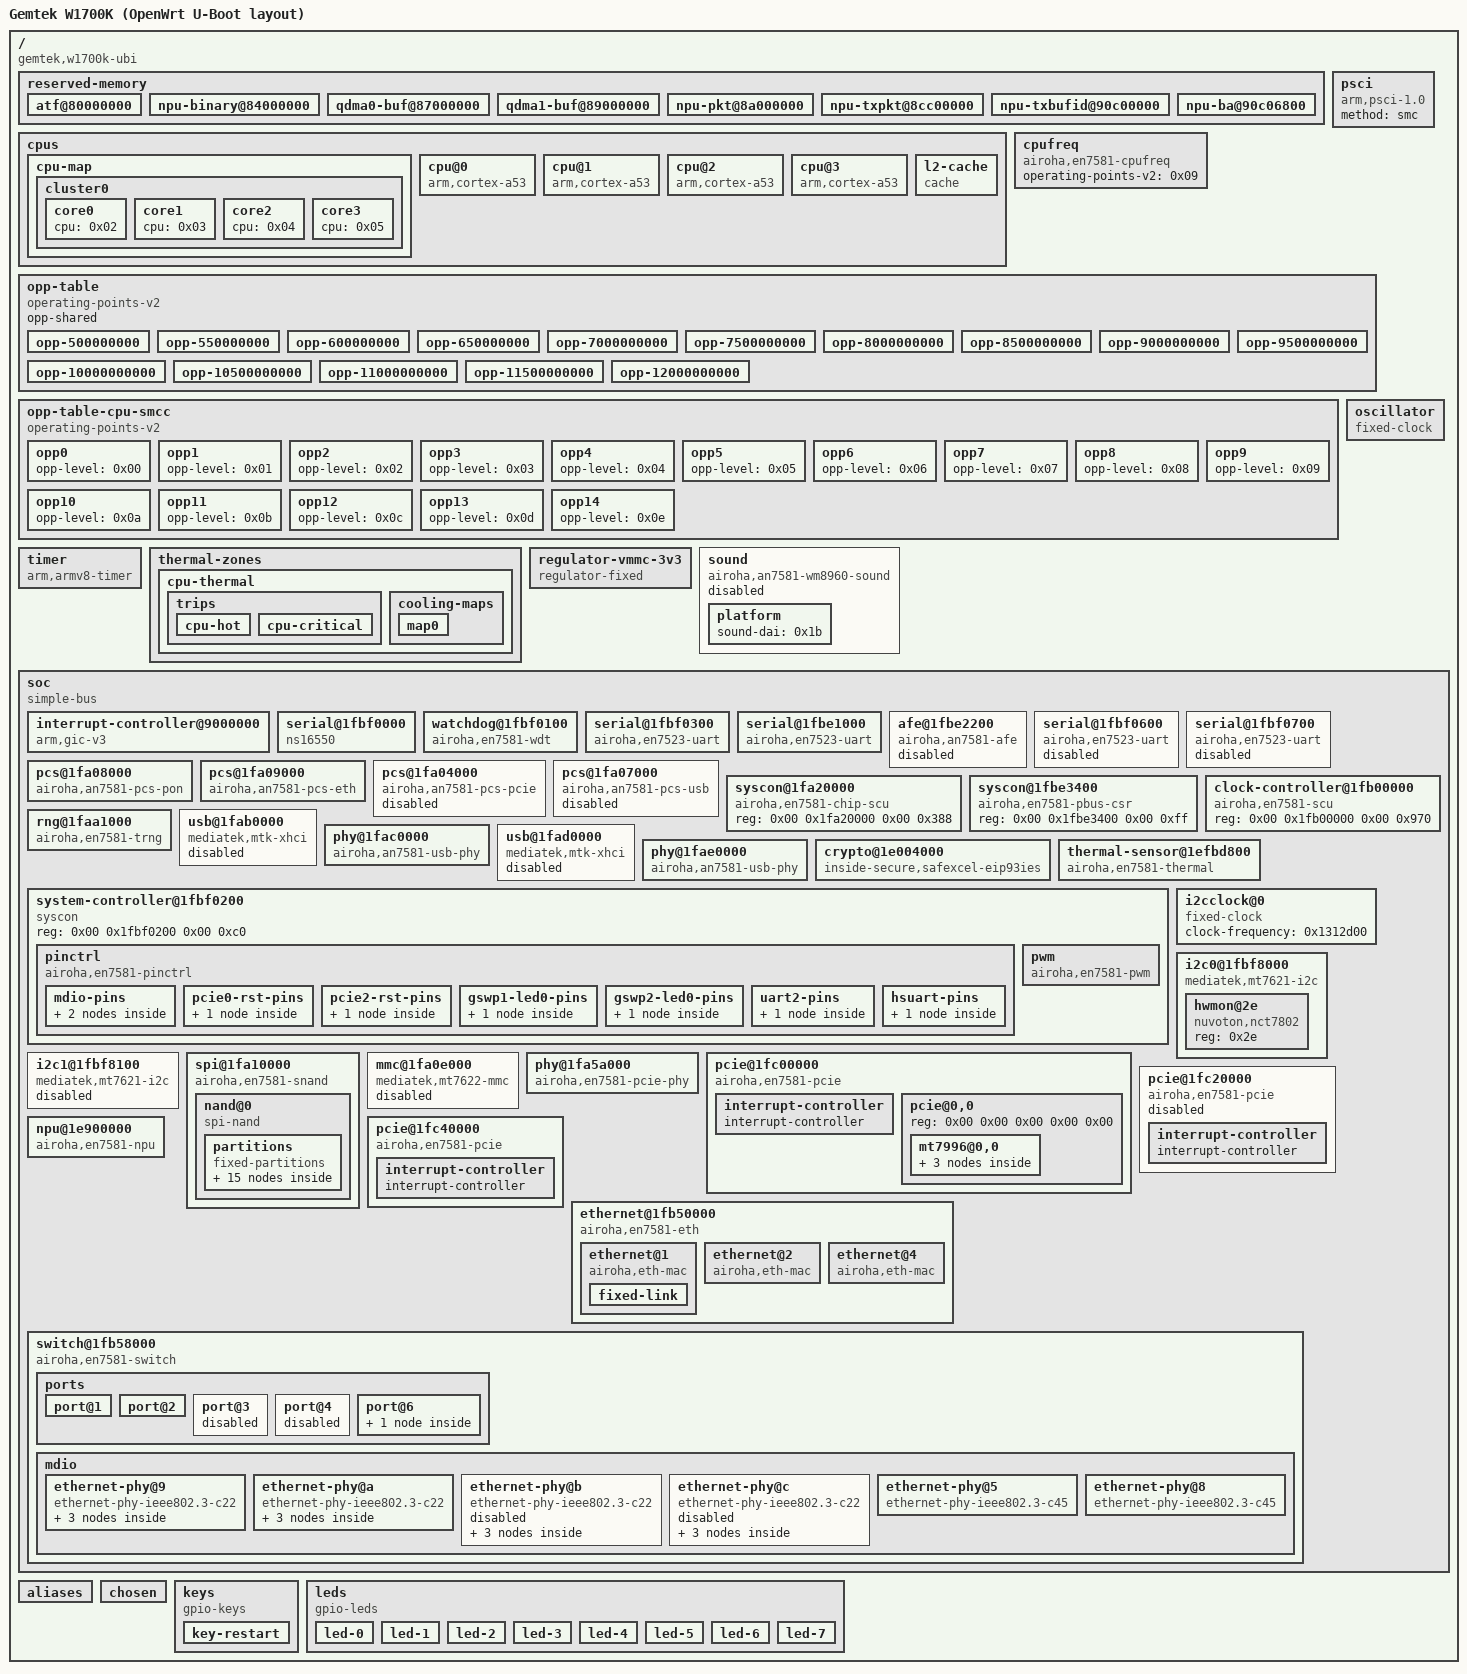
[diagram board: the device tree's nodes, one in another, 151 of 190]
/dts-v1/;

/ {
	interrupt-parent = <0x01>;
	#address-cells = <0x02>;
	#size-cells = <0x02>;
	model = "Gemtek W1700K (OpenWrt U-Boot layout)";
	compatible = "gemtek,w1700k-ubi", "airoha,an7581", "airoha,en7581";

	reserved-memory {
		#address-cells = <0x02>;
		#size-cells = <0x02>;
		ranges;

		atf@80000000 {
			no-map;
			reg = <0x00 0x80000000 0x00 0x200000>;
		};

		npu-binary@84000000 {
			no-map;
			reg = <0x00 0x84000000 0x00 0xa00000>;
			phandle = <0x31>;
		};

		qdma0-buf@87000000 {
			no-map;
			reg = <0x00 0x87000000 0x00 0x2000000>;
			phandle = <0x36>;
		};

		qdma1-buf@89000000 {
			no-map;
			reg = <0x00 0x89000000 0x00 0x1000000>;
			phandle = <0x37>;
		};

		npu-pkt@8a000000 {
			no-map;
			reg = <0x00 0x8a000000 0x00 0x2c00000>;
			phandle = <0x32>;
		};

		npu-txpkt@8cc00000 {
			no-map;
			reg = <0x00 0x8cc00000 0x00 0x4000000>;
			phandle = <0x33>;
		};

		npu-txbufid@90c00000 {
			no-map;
			reg = <0x00 0x90c00000 0x00 0x6800>;
			phandle = <0x34>;
		};

		npu-ba@90c06800 {
			no-map;
			reg = <0x00 0x90c06800 0x00 0x200000>;
			phandle = <0x35>;
		};
	};

	psci {
		compatible = "arm,psci-1.0";
		method = "smc";
	};

	cpus {
		#address-cells = <0x01>;
		#size-cells = <0x00>;

		cpu-map {

			cluster0 {

				core0 {
					cpu = <0x02>;
				};

				core1 {
					cpu = <0x03>;
				};

				core2 {
					cpu = <0x04>;
				};

				core3 {
					cpu = <0x05>;
				};
			};
		};

		cpu@0 {
			device_type = "cpu";
			compatible = "arm,cortex-a53";
			reg = <0x00>;
			operating-points-v2 = <0x06>;
			enable-method = "psci";
			clocks = <0x07>;
			clock-names = "cpu";
			power-domains = <0x07>;
			power-domain-names = "perf";
			next-level-cache = <0x08>;
			#cooling-cells = <0x02>;
			phandle = <0x02>;
		};

		cpu@1 {
			device_type = "cpu";
			compatible = "arm,cortex-a53";
			reg = <0x01>;
			operating-points-v2 = <0x06>;
			enable-method = "psci";
			clocks = <0x07>;
			clock-names = "cpu";
			power-domains = <0x07>;
			power-domain-names = "perf";
			next-level-cache = <0x08>;
			#cooling-cells = <0x02>;
			phandle = <0x03>;
		};

		cpu@2 {
			device_type = "cpu";
			compatible = "arm,cortex-a53";
			reg = <0x02>;
			operating-points-v2 = <0x06>;
			enable-method = "psci";
			clocks = <0x07>;
			clock-names = "cpu";
			power-domains = <0x07>;
			power-domain-names = "perf";
			next-level-cache = <0x08>;
			#cooling-cells = <0x02>;
			phandle = <0x04>;
		};

		cpu@3 {
			device_type = "cpu";
			compatible = "arm,cortex-a53";
			reg = <0x03>;
			operating-points-v2 = <0x06>;
			enable-method = "psci";
			clocks = <0x07>;
			clock-names = "cpu";
			power-domains = <0x07>;
			power-domain-names = "perf";
			next-level-cache = <0x08>;
			#cooling-cells = <0x02>;
			phandle = <0x05>;
		};

		l2-cache {
			compatible = "cache";
			cache-size = <0x80000>;
			cache-line-size = <0x40>;
			cache-level = <0x02>;
			cache-unified;
			phandle = <0x08>;
		};
	};

	cpufreq {
		compatible = "airoha,en7581-cpufreq";
		operating-points-v2 = <0x09>;
		#power-domain-cells = <0x00>;
		#clock-cells = <0x00>;
		phandle = <0x07>;
	};

	opp-table {
		compatible = "operating-points-v2";
		opp-shared;
		phandle = <0x06>;

		opp-500000000 {
			opp-hz = <0x00 0x1dcd6500>;
			required-opps = <0x0a>;
		};

		opp-550000000 {
			opp-hz = <0x00 0x20c85580>;
			required-opps = <0x0b>;
		};

		opp-600000000 {
			opp-hz = <0x00 0x23c34600>;
			required-opps = <0x0c>;
		};

		opp-650000000 {
			opp-hz = <0x00 0x26be3680>;
			required-opps = <0x0d>;
		};

		opp-7000000000 {
			opp-hz = <0x00 0x29b92700>;
			required-opps = <0x0e>;
		};

		opp-7500000000 {
			opp-hz = <0x00 0x2cb41780>;
			required-opps = <0x0f>;
		};

		opp-8000000000 {
			opp-hz = <0x00 0x2faf0800>;
			required-opps = <0x10>;
		};

		opp-8500000000 {
			opp-hz = <0x00 0x32a9f880>;
			required-opps = <0x11>;
		};

		opp-9000000000 {
			opp-hz = <0x00 0x35a4e900>;
			required-opps = <0x12>;
		};

		opp-9500000000 {
			opp-hz = <0x00 0x389fd980>;
			required-opps = <0x13>;
		};

		opp-10000000000 {
			opp-hz = <0x00 0x3b9aca00>;
			required-opps = <0x14>;
		};

		opp-10500000000 {
			opp-hz = <0x00 0x3e95ba80>;
			required-opps = <0x15>;
		};

		opp-11000000000 {
			opp-hz = <0x00 0x4190ab00>;
			required-opps = <0x16>;
		};

		opp-11500000000 {
			opp-hz = <0x00 0x448b9b80>;
			required-opps = <0x17>;
		};

		opp-12000000000 {
			opp-hz = <0x00 0x47868c00>;
			required-opps = <0x18>;
		};
	};

	opp-table-cpu-smcc {
		compatible = "operating-points-v2";
		phandle = <0x09>;

		opp0 {
			opp-level = <0x00>;
			phandle = <0x0a>;
		};

		opp1 {
			opp-level = <0x01>;
			phandle = <0x0b>;
		};

		opp2 {
			opp-level = <0x02>;
			phandle = <0x0c>;
		};

		opp3 {
			opp-level = <0x03>;
			phandle = <0x0d>;
		};

		opp4 {
			opp-level = <0x04>;
			phandle = <0x0e>;
		};

		opp5 {
			opp-level = <0x05>;
			phandle = <0x0f>;
		};

		opp6 {
			opp-level = <0x06>;
			phandle = <0x10>;
		};

		opp7 {
			opp-level = <0x07>;
			phandle = <0x11>;
		};

		opp8 {
			opp-level = <0x08>;
			phandle = <0x12>;
		};

		opp9 {
			opp-level = <0x09>;
			phandle = <0x13>;
		};

		opp10 {
			opp-level = <0x0a>;
			phandle = <0x14>;
		};

		opp11 {
			opp-level = <0x0b>;
			phandle = <0x15>;
		};

		opp12 {
			opp-level = <0x0c>;
			phandle = <0x16>;
		};

		opp13 {
			opp-level = <0x0d>;
			phandle = <0x17>;
		};

		opp14 {
			opp-level = <0x0e>;
			phandle = <0x18>;
		};
	};

	timer {
		compatible = "arm,armv8-timer";
		interrupt-parent = <0x01>;
		interrupts = <0x01 0x0d 0x08 0x01 0x0e 0x08 0x01 0x0b 0x08 0x01 0x0a 0x08>;
	};

	thermal-zones {

		cpu-thermal {
			polling-delay-passive = <0x00>;
			polling-delay = <0x00>;
			thermal-sensors = <0x19 0x00>;

			trips {

				cpu-hot {
					temperature = <0x17318>;
					hysteresis = <0x3e8>;
					type = "hot";
					phandle = <0x1a>;
				};

				cpu-critical {
					temperature = <0x1adb0>;
					hysteresis = <0x3e8>;
					type = "critical";
				};
			};

			cooling-maps {

				map0 {
					trip = <0x1a>;
					cooling-device = <0x02 0xffffffff 0xffffffff 0x03 0xffffffff 0xffffffff 0x04 0xffffffff 0xffffffff 0x05 0xffffffff 0xffffffff>;
				};
			};
		};
	};

	oscillator {
		compatible = "fixed-clock";
		#clock-cells = <0x00>;
		clock-frequency = <0x17d7840>;
		clock-output-names = "clkxtal";
		phandle = <0x24>;
	};

	regulator-vmmc-3v3 {
		compatible = "regulator-fixed";
		regulator-name = "vmmc";
		regulator-min-microvolt = <0x325aa0>;
		regulator-max-microvolt = <0x325aa0>;
		regulator-always-on;
		phandle = <0x25>;
	};

	sound {
		compatible = "airoha,an7581-wm8960-sound";
		status = "disabled";

		platform {
			sound-dai = <0x1b>;
		};
	};

	soc {
		compatible = "simple-bus";
		#address-cells = <0x02>;
		#size-cells = <0x02>;
		ranges;

		interrupt-controller@9000000 {
			compatible = "arm,gic-v3";
			interrupt-controller;
			#interrupt-cells = <0x03>;
			#address-cells = <0x01>;
			#size-cells = <0x01>;
			reg = <0x00 0x9000000 0x00 0x20000 0x00 0x9080000 0x00 0x80000 0x00 0x9400000 0x00 0x2000 0x00 0x9500000 0x00 0x2000 0x00 0x9600000 0x00 0x20000>;
			interrupts = <0x01 0x09 0x08>;
			phandle = <0x01>;
		};

		serial@1fbf0000 {
			compatible = "ns16550";
			reg = <0x00 0x1fbf0000 0x00 0x30>;
			reg-io-width = <0x04>;
			reg-shift = <0x02>;
			interrupts = <0x00 0x12 0x04>;
			clock-frequency = <0x1c2000>;
		};

		watchdog@1fbf0100 {
			compatible = "airoha,en7581-wdt";
			reg = <0x00 0x1fbf0100 0x00 0x38>;
			clocks = <0x1c 0x02>;
			clock-names = "bus";
		};

		serial@1fbf0300 {
			compatible = "airoha,en7523-uart";
			reg = <0x00 0x1fbf0300 0x00 0x30>;
			reg-io-width = <0x04>;
			reg-shift = <0x02>;
			interrupts = <0x00 0x20 0x04>;
			clock-frequency = <0x708000>;
			status = "okay";
			pinctrl-names = "default";
			pinctrl-0 = <0x1d>;
		};

		serial@1fbe1000 {
			compatible = "airoha,en7523-uart";
			reg = <0x00 0x1fbe1000 0x00 0x40>;
			reg-io-width = <0x04>;
			reg-shift = <0x02>;
			interrupts = <0x00 0x36 0x04>;
			clock-frequency = <0x708000>;
			status = "okay";
			pinctrl-names = "default";
			pinctrl-0 = <0x1e>;
		};

		afe@1fbe2200 {
			compatible = "airoha,an7581-afe";
			reg = <0x00 0x1fbe2200 0x00 0x9000>;
			interrupts = <0x00 0x30 0x04>;
			status = "disabled";
			phandle = <0x1b>;
		};

		serial@1fbf0600 {
			compatible = "airoha,en7523-uart";
			reg = <0x00 0x1fbf0600 0x00 0x30>;
			reg-io-width = <0x04>;
			reg-shift = <0x02>;
			interrupts = <0x00 0x3d 0x04>;
			clock-frequency = <0x708000>;
			status = "disabled";
		};

		serial@1fbf0700 {
			compatible = "airoha,en7523-uart";
			reg = <0x00 0x1fbf0700 0x00 0x30>;
			reg-io-width = <0x04>;
			reg-shift = <0x02>;
			interrupts = <0x00 0x12 0x04>;
			clock-frequency = <0x708000>;
			status = "disabled";
		};

		pcs@1fa08000 {
			compatible = "airoha,an7581-pcs-pon";
			reg = <0x00 0x1fa08000 0x00 0x1000 0x00 0x1fa80000 0x00 0x60 0x00 0x1fa80a00 0x00 0x164 0x00 0x1fa84000 0x00 0x450 0x00 0x1fa85900 0x00 0x338 0x00 0x1fa86000 0x00 0x300 0x00 0x1fa8a000 0x00 0x1000 0x00 0x1fa8b000 0x00 0x1000>;
			reg-names = "pcs_mac", "hsgmii_an", "hsgmii_pcs", "multi_sgmii", "usxgmii", "hsgmii_rate_adp", "pcs_ana", "pcs_pma";
			resets = <0x1c 0x34 0x1c 0x00>;
			reset-names = "mac", "phy";
			airoha,scu = <0x1c>;
			#pcs-cells = <0x00>;
			status = "okay";
			phandle = <0x38>;
		};

		pcs@1fa09000 {
			compatible = "airoha,an7581-pcs-eth";
			reg = <0x00 0x1fa09000 0x00 0x1000 0x00 0x1fa70000 0x00 0x60 0x00 0x1fa70a00 0x00 0x164 0x00 0x1fa74000 0x00 0x450 0x00 0x1fa75900 0x00 0x338 0x00 0x1fa76000 0x00 0x300 0x00 0x1fa7a000 0x00 0x1000 0x00 0x1fa7b000 0x00 0x1000>;
			reg-names = "pcs_mac", "hsgmii_an", "hsgmii_pcs", "multi_sgmii", "usxgmii", "hsgmii_rate_adp", "pcs_ana", "pcs_pma";
			resets = <0x1c 0x06 0x1c 0x07>;
			reset-names = "mac", "phy";
			airoha,scu = <0x1c>;
			#pcs-cells = <0x00>;
			status = "okay";
			phandle = <0x3b>;
		};

		pcs@1fa04000 {
			compatible = "airoha,an7581-pcs-pcie";
			reg = <0x00 0x1fa04000 0x00 0x1000 0x00 0x1fa50000 0x00 0x60 0x00 0x1fa50a00 0x00 0x164 0x00 0x1fa54000 0x00 0x450 0x00 0x1fa55900 0x00 0x338 0x00 0x1fa56000 0x00 0x300 0x00 0x1fa05000 0x00 0x1000 0x00 0x1fa60000 0x00 0x60 0x00 0x1fa60a00 0x00 0x164 0x00 0x1fa64000 0x00 0x450 0x00 0x1fa65900 0x00 0x338 0x00 0x1fa66000 0x00 0x300 0x00 0x1fa5a000 0x00 0x1000 0x00 0x1fa5b000 0x00 0x1000 0x00 0x1fa5c000 0x00 0x1000>;
			reg-names = "pcs_mac0", "hsgmii_an0", "hsgmii_pcs0", "multi_sgmii0", "usxgmii0", "hsgmii_rate_adp0", "pcs_mac1", "hsgmii_an1", "hsgmii_pcs1", "multi_sgmii1", "usxgmii1", "hsgmii_rate_adp1", "pcs_ana", "pcs_pma0", "pcs_pma1";
			airoha,scu = <0x1c>;
			#pcs-cells = <0x01>;
			status = "disabled";
		};

		pcs@1fa07000 {
			compatible = "airoha,an7581-pcs-usb";
			reg = <0x00 0x1fa07000 0x00 0x1000 0x00 0x1fa90000 0x00 0x60 0x00 0x1fa90a00 0x00 0x164 0x00 0x1fa94000 0x00 0x450 0x00 0x1fa96000 0x00 0x300 0x00 0x1fa9a000 0x00 0x600>;
			reg-names = "pcs_mac", "hsgmii_an", "hsgmii_pcs", "multi_sgmii", "hsgmii_rate_adp", "pcs_ana";
			phys = <0x1f 0x04>;
			airoha,scu = <0x1c>;
			#pcs-cells = <0x00>;
			status = "disabled";
		};

		syscon@1fa20000 {
			compatible = "airoha,en7581-chip-scu", "syscon";
			reg = <0x00 0x1fa20000 0x00 0x388>;
			phandle = <0x21>;
		};

		syscon@1fbe3400 {
			compatible = "airoha,en7581-pbus-csr", "syscon";
			reg = <0x00 0x1fbe3400 0x00 0xff>;
			phandle = <0x27>;
		};

		clock-controller@1fb00000 {
			compatible = "airoha,en7581-scu", "syscon";
			reg = <0x00 0x1fb00000 0x00 0x970>;
			#clock-cells = <0x01>;
			#reset-cells = <0x01>;
			phandle = <0x1c>;
		};

		rng@1faa1000 {
			compatible = "airoha,en7581-trng";
			reg = <0x00 0x1faa1000 0x00 0xc04>;
			interrupts = <0x00 0x23 0x04>;
		};

		usb@1fab0000 {
			compatible = "mediatek,mtk-xhci";
			reg = <0x00 0x1fab0000 0x00 0x3e00 0x00 0x1fab3e00 0x00 0x100>;
			reg-names = "mac", "ippc";
			interrupts = <0x00 0x21 0x04>;
			phys = <0x1f 0x03 0x1f 0x04>;
			status = "disabled";
		};

		phy@1fac0000 {
			compatible = "airoha,an7581-usb-phy";
			reg = <0x00 0x1fac0000 0x00 0x10000>;
			airoha,scu = <0x1c>;
			airoha,usb2-monitor-clk-sel = <0x01>;
			airoha,serdes-port = <0x02>;
			#phy-cells = <0x01>;
			phandle = <0x1f>;
		};

		usb@1fad0000 {
			compatible = "mediatek,mtk-xhci";
			reg = <0x00 0x1fad0000 0x00 0x3e00 0x00 0x1fad3e00 0x00 0x100>;
			reg-names = "mac", "ippc";
			interrupts = <0x00 0x96 0x04>;
			phys = <0x20 0x03 0x20 0x04>;
			status = "disabled";
		};

		phy@1fae0000 {
			compatible = "airoha,an7581-usb-phy";
			reg = <0x00 0x1fae0000 0x00 0x10000>;
			airoha,scu = <0x1c>;
			airoha,usb2-monitor-clk-sel = <0x02>;
			airoha,serdes-port = <0x03>;
			#phy-cells = <0x01>;
			phandle = <0x20>;
		};

		crypto@1e004000 {
			compatible = "inside-secure,safexcel-eip93ies";
			reg = <0x00 0x1fb70000 0x00 0x1000>;
			interrupts = <0x00 0x2c 0x04>;
		};

		thermal-sensor@1efbd800 {
			compatible = "airoha,en7581-thermal";
			reg = <0x00 0x1efbd000 0x00 0xd5c>;
			interrupts = <0x00 0x17 0x04>;
			airoha,chip-scu = <0x21>;
			#thermal-sensor-cells = <0x00>;
			phandle = <0x19>;
		};

		system-controller@1fbf0200 {
			compatible = "syscon", "simple-mfd";
			reg = <0x00 0x1fbf0200 0x00 0xc0>;

			pinctrl {
				compatible = "airoha,en7581-pinctrl";
				interrupt-parent = <0x01>;
				interrupts = <0x00 0x1a 0x04>;
				gpio-controller;
				#gpio-cells = <0x02>;
				interrupt-controller;
				#interrupt-cells = <0x02>;
				gpio-ranges = <0x22 0x00 0x0d 0x2f>;
				phandle = <0x22>;

				mdio-pins {
					phandle = <0x3d>;

					mux {
						function = "mdio";
						groups = "mdio";
					};

					conf {
						pins = "gpio2";
						output-high;
					};
				};

				pcie0-rst-pins {
					phandle = <0x29>;

					conf {
						pins = "pcie_reset0";
						drive-open-drain = <0x01>;
					};
				};

				pcie2-rst-pins {
					phandle = <0x30>;

					conf {
						pins = "pcie_reset2";
						drive-open-drain = <0x01>;
					};
				};

				gswp1-led0-pins {
					phandle = <0x43>;

					mux {
						function = "phy1_led0";
						pins = "gpio33";
					};
				};

				gswp2-led0-pins {
					phandle = <0x44>;

					mux {
						function = "phy2_led0";
						pins = "gpio34";
					};
				};

				uart2-pins {
					phandle = <0x1d>;

					mux {
						function = "uart";
						groups = "uart2";
					};
				};

				hsuart-pins {
					phandle = <0x1e>;

					mux {
						function = "uart";
						groups = "hsuart";
					};
				};
			};

			pwm {
				compatible = "airoha,en7581-pwm";
				#pwm-cells = <0x03>;
			};
		};

		i2cclock@0 {
			#clock-cells = <0x00>;
			compatible = "fixed-clock";
			clock-frequency = <0x1312d00>;
			phandle = <0x23>;
		};

		i2c0@1fbf8000 {
			compatible = "mediatek,mt7621-i2c";
			reg = <0x00 0x1fbf8000 0x00 0x100>;
			clocks = <0x23>;
			clock-frequency = <0x186a0>;
			#address-cells = <0x01>;
			#size-cells = <0x00>;
			status = "okay";

			hwmon@2e {
				compatible = "nuvoton,nct7802";
				reg = <0x2e>;
			};
		};

		i2c1@1fbf8100 {
			compatible = "mediatek,mt7621-i2c";
			reg = <0x00 0x1fbf8100 0x00 0x100>;
			clocks = <0x23>;
			clock-frequency = <0x186a0>;
			#address-cells = <0x01>;
			#size-cells = <0x00>;
			status = "disabled";
		};

		spi@1fa10000 {
			compatible = "airoha,en7581-snand";
			reg = <0x00 0x1fa10000 0x00 0x140 0x00 0x1fa11000 0x00 0x160>;
			clocks = <0x1c 0x04>;
			clock-names = "spi";
			#address-cells = <0x01>;
			#size-cells = <0x00>;
			status = "okay";

			nand@0 {
				compatible = "spi-nand";
				reg = <0x00>;
				spi-max-frequency = <0x2faf080>;
				spi-tx-bus-width = <0x01>;
				spi-rx-bus-width = <0x02>;
				#address-cells = <0x01>;
				#size-cells = <0x01>;

				partitions {
					compatible = "fixed-partitions";
					#address-cells = <0x01>;
					#size-cells = <0x01>;

					partition@0 {
						label = "vendor";
						reg = <0x00 0x600000>;
						read-only;
					};

					partition@600000 {
						label = "chainloader";
						reg = <0x600000 0x100000>;
						read-only;
					};

					partition@700000 {
						label = "ubi";
						reg = <0x700000 0x1b700000>;
						compatible = "linux,ubi";

						volumes {

							ubi-volume-ubootenv {
								volname = "ubootenv";

								nvmem-layout {
									compatible = "u-boot,env-redundant-bool";
								};
							};

							ubi-volume-ubootenv2 {
								volname = "ubootenv2";

								nvmem-layout {
									compatible = "u-boot,env-redundant-bool";
								};
							};

							ubi-volume-fit {
								volname = "fit";
								phandle = <0x45>;
							};

							ubi-volume-factory {
								volname = "factory";

								nvmem-layout {
									compatible = "fixed-layout";
									#address-cells = <0x01>;
									#size-cells = <0x01>;

									eeprom@0 {
										reg = <0x00 0x1e00>;
										phandle = <0x2a>;
									};

									macaddr@5000 {
										reg = <0x5000 0x06>;
										phandle = <0x3a>;
									};

									macaddr@6000 {
										compatible = "mac-base";
										reg = <0x6000 0x06>;
										#nvmem-cell-cells = <0x01>;
										phandle = <0x2d>;
									};
								};
							};
						};
					};

					reserved_bmt@1be00000 {
						label = "reserved_bmt";
						reg = <0x1be00000 0x4200000>;
						read-only;
					};
				};
			};
		};

		mmc@1fa0e000 {
			compatible = "mediatek,mt7622-mmc";
			reg = <0x00 0x1fa0e000 0x00 0x1000 0x00 0x1fa0c000 0x00 0x60>;
			interrupts = <0x00 0xaa 0x04>;
			clocks = <0x1c 0x08 0x24>;
			clock-names = "source", "hclk";
			bus-width = <0x04>;
			max-frequency = <0x3197500>;
			vmmc-supply = <0x25>;
			disable-wp;
			cap-mmc-highspeed;
			non-removable;
			status = "disabled";
		};

		phy@1fa5a000 {
			compatible = "airoha,en7581-pcie-phy";
			reg = <0x00 0x1fa5a000 0x00 0xfff 0x00 0x1fa5b000 0x00 0xfff 0x00 0x1fa5c000 0x00 0xfff 0x00 0x1fc10044 0x00 0x04 0x00 0x1fc30044 0x00 0x04 0x00 0x1fc15030 0x00 0x104>;
			reg-names = "csr-2l", "pma0", "pma1", "p0-xr-dtime", "p1-xr-dtime", "rx-aeq";
			#phy-cells = <0x00>;
			phandle = <0x26>;
		};

		pcie@1fc00000 {
			compatible = "airoha,en7581-pcie";
			device_type = "pci";
			linux,pci-domain = <0x00>;
			#address-cells = <0x03>;
			#size-cells = <0x02>;
			reg = <0x00 0x1fc00000 0x00 0x1670>;
			reg-names = "pcie-mac";
			clocks = <0x1c 0x07>;
			clock-names = "sys-ck";
			phys = <0x26>;
			phy-names = "pcie-phy";
			ranges = <0x2000000 0x00 0x20000000 0x00 0x20000000 0x00 0x4000000>;
			resets = <0x1c 0x30 0x1c 0x31 0x1c 0x19>;
			reset-names = "phy-lane0", "phy-lane1", "phy-lane2";
			mediatek,pbus-csr = <0x27 0x00 0x04>;
			airoha,np-scu = <0x1c>;
			interrupts = <0x00 0x27 0x04>;
			bus-range = <0x00 0xff>;
			#interrupt-cells = <0x01>;
			interrupt-map-mask = <0x00 0x00 0x00 0x07>;
			interrupt-map = <0x00 0x00 0x00 0x01 0x28 0x00 0x00 0x00 0x00 0x02 0x28 0x01 0x00 0x00 0x00 0x03 0x28 0x02 0x00 0x00 0x00 0x04 0x28 0x03>;
			status = "okay";
			airoha,x2-mode;
			pinctrl-names = "default";
			pinctrl-0 = <0x29>;

			interrupt-controller {
				interrupt-controller;
				#address-cells = <0x00>;
				#interrupt-cells = <0x01>;
				phandle = <0x28>;
			};

			pcie@0,0 {
				reg = <0x00 0x00 0x00 0x00 0x00>;
				device_type = "pci";
				#address-cells = <0x03>;
				#size-cells = <0x02>;

				mt7996@0,0 {
					reg = <0x00 0x00 0x00 0x00 0x00>;
					#address-cells = <0x01>;
					#size-cells = <0x00>;
					nvmem-cells = <0x2a>;
					nvmem-cell-names = "eeprom";
					airoha,npu = <0x2b>;
					airoha,eth = <0x2c>;

					band@0 {
						reg = <0x00>;
						nvmem-cells = <0x2d 0x01>;
						nvmem-cell-names = "mac-address";
					};

					band@1 {
						reg = <0x01>;
						nvmem-cells = <0x2d 0x02>;
						nvmem-cell-names = "mac-address";
					};

					band@2 {
						reg = <0x02>;
						nvmem-cells = <0x2d 0x03>;
						nvmem-cell-names = "mac-address";
					};
				};
			};
		};

		pcie@1fc20000 {
			compatible = "airoha,en7581-pcie";
			device_type = "pci";
			linux,pci-domain = <0x01>;
			#address-cells = <0x03>;
			#size-cells = <0x02>;
			reg = <0x00 0x1fc20000 0x00 0x1670>;
			reg-names = "pcie-mac";
			clocks = <0x1c 0x07>;
			clock-names = "sys-ck";
			phys = <0x26>;
			phy-names = "pcie-phy";
			ranges = <0x2000000 0x00 0x24000000 0x00 0x24000000 0x00 0x4000000>;
			resets = <0x1c 0x30 0x1c 0x31 0x1c 0x19>;
			reset-names = "phy-lane0", "phy-lane1", "phy-lane2";
			mediatek,pbus-csr = <0x27 0x08 0x0c>;
			interrupts = <0x00 0x28 0x04>;
			bus-range = <0x00 0xff>;
			#interrupt-cells = <0x01>;
			interrupt-map-mask = <0x00 0x00 0x00 0x07>;
			interrupt-map = <0x00 0x00 0x00 0x01 0x2e 0x00 0x00 0x00 0x00 0x02 0x2e 0x01 0x00 0x00 0x00 0x03 0x2e 0x02 0x00 0x00 0x00 0x04 0x2e 0x03>;
			status = "disabled";

			interrupt-controller {
				interrupt-controller;
				#address-cells = <0x00>;
				#interrupt-cells = <0x01>;
				phandle = <0x2e>;
			};
		};

		pcie@1fc40000 {
			compatible = "airoha,en7581-pcie";
			device_type = "pci";
			linux,pci-domain = <0x02>;
			#address-cells = <0x03>;
			#size-cells = <0x02>;
			reg = <0x00 0x1fc40000 0x00 0x1670>;
			reg-names = "pcie-mac";
			clocks = <0x1c 0x07>;
			clock-names = "sys-ck";
			phys = <0x20 0x04>;
			phy-names = "pcie-phy";
			ranges = <0x2000000 0x00 0x28000000 0x00 0x28000000 0x00 0x4000000>;
			resets = <0x1c 0x30 0x1c 0x31 0x1c 0x19>;
			reset-names = "phy-lane0", "phy-lane1", "phy-lane2";
			mediatek,pbus-csr = <0x27 0x10 0x14>;
			airoha,np-scu = <0x1c>;
			interrupts = <0x00 0x29 0x04>;
			bus-range = <0x00 0xff>;
			#interrupt-cells = <0x01>;
			interrupt-map-mask = <0x00 0x00 0x00 0x07>;
			interrupt-map = <0x00 0x00 0x00 0x01 0x2f 0x00 0x00 0x00 0x00 0x02 0x2f 0x01 0x00 0x00 0x00 0x03 0x2f 0x02 0x00 0x00 0x00 0x04 0x2f 0x03>;
			status = "okay";
			pinctrl-names = "default";
			pinctrl-0 = <0x30>;

			interrupt-controller {
				interrupt-controller;
				#address-cells = <0x00>;
				#interrupt-cells = <0x01>;
				phandle = <0x2f>;
			};
		};

		npu@1e900000 {
			compatible = "airoha,en7581-npu";
			reg = <0x00 0x1e900000 0x00 0x313000>;
			interrupts = <0x00 0x7d 0x04 0x00 0x67 0x04 0x00 0x6d 0x04 0x00 0x71 0x04 0x00 0x75 0x04 0x00 0x86 0x04 0x00 0x87 0x04 0x00 0x88 0x04 0x00 0x89 0x04 0x00 0x76 0x04 0x00 0x77 0x04 0x00 0x78 0x04 0x00 0x79 0x04 0x00 0x7a 0x04 0x00 0x7b 0x04>;
			memory-region = <0x31 0x32 0x33 0x34 0x35>;
			memory-region-names = "binary", "pkt", "tx-pkt", "tx-bufid", "ba";
			status = "okay";
			firmware-name = "airoha/en7581_MT7996_npu_rv32.bin", "airoha/en7581_MT7996_npu_data.bin";
			phandle = <0x2b>;
		};

		ethernet@1fb50000 {
			compatible = "airoha,en7581-eth";
			reg = <0x00 0x1fb50000 0x00 0x2600 0x00 0x1fb54000 0x00 0x2000 0x00 0x1fb56000 0x00 0x2000>;
			reg-names = "fe", "qdma0", "qdma1";
			resets = <0x1c 0x2c 0x1c 0x1e 0x1c 0x1f 0x1c 0x06 0x1c 0x0f 0x1c 0x10 0x1c 0x11 0x1c 0x1a>;
			reset-names = "fe", "pdma", "qdma", "xsi-mac", "hsi0-mac", "hsi1-mac", "hsi-mac", "xfp-mac";
			interrupts = <0x00 0x25 0x04 0x00 0x37 0x04 0x00 0x38 0x04 0x00 0x39 0x04 0x00 0x26 0x04 0x00 0x3a 0x04 0x00 0x3b 0x04 0x00 0x3c 0x04 0x00 0x31 0x04 0x00 0x40 0x04>;
			memory-region = <0x36 0x37>;
			memory-region-names = "qdma0-buf", "qdma1-buf";
			airoha,npu = <0x2b>;
			status = "okay";
			#address-cells = <0x01>;
			#size-cells = <0x00>;
			phandle = <0x2c>;

			ethernet@1 {
				compatible = "airoha,eth-mac";
				reg = <0x01>;
				phy-mode = "internal";
				status = "okay";
				nvmem-cells = <0x2d 0x00>;
				nvmem-cell-names = "mac-address";
				phandle = <0x42>;

				fixed-link {
					speed = <0x2710>;
					full-duplex;
					pause;
				};
			};

			ethernet@2 {
				compatible = "airoha,eth-mac";
				reg = <0x02>;
				pcs-handle = <0x38>;
				status = "okay";
				managed = "in-band-status";
				phy-handle = <0x39>;
				phy-mode = "usxgmii";
				nvmem-cells = <0x3a 0x00>;
				nvmem-cell-names = "mac-address";
				openwrt,netdev-name = "wan";
			};

			ethernet@4 {
				compatible = "airoha,eth-mac";
				reg = <0x04>;
				pcs-handle = <0x3b>;
				status = "okay";
				managed = "in-band-status";
				phy-handle = <0x3c>;
				phy-mode = "usxgmii";
				nvmem-cells = <0x2d 0x00>;
				nvmem-cell-names = "mac-address";
				openwrt,netdev-name = "lan2";
			};
		};

		switch@1fb58000 {
			compatible = "airoha,en7581-switch";
			reg = <0x00 0x1fb58000 0x00 0x8000>;
			resets = <0x1c 0x2e>;
			interrupt-controller;
			#interrupt-cells = <0x01>;
			interrupt-parent = <0x01>;
			interrupts = <0x00 0x1f 0x04>;
			status = "okay";
			#address-cells = <0x01>;
			#size-cells = <0x01>;
			pinctrl-names = "default";
			pinctrl-0 = <0x3d>;

			ports {
				#address-cells = <0x01>;
				#size-cells = <0x00>;

				port@1 {
					reg = <0x01>;
					phy-mode = "internal";
					phy-handle = <0x3e>;
					status = "okay";
					label = "lan3";
				};

				port@2 {
					reg = <0x02>;
					phy-mode = "internal";
					phy-handle = <0x3f>;
					status = "okay";
					label = "lan4";
				};

				port@3 {
					reg = <0x03>;
					phy-mode = "internal";
					phy-handle = <0x40>;
					status = "disabled";
				};

				port@4 {
					reg = <0x04>;
					phy-mode = "internal";
					phy-handle = <0x41>;
					status = "disabled";
				};

				port@6 {
					reg = <0x06>;
					ethernet = <0x42>;
					phy-mode = "internal";

					fixed-link {
						speed = <0x2710>;
						full-duplex;
						pause;
					};
				};
			};

			mdio {
				#address-cells = <0x01>;
				#size-cells = <0x00>;

				ethernet-phy@9 {
					compatible = "ethernet-phy-ieee802.3-c22";
					reg = <0x09>;
					phy-mode = "internal";
					status = "okay";
					interrupts = <0x01>;
					pinctrl-names = "gbe-led";
					pinctrl-0 = <0x43>;
					phandle = <0x3e>;

					leds {
						#address-cells = <0x01>;
						#size-cells = <0x00>;

						led@0 {
							reg = <0x00>;
							status = "disabled";
						};

						led@1 {
							reg = <0x01>;
							status = "disabled";
						};
					};
				};

				ethernet-phy@a {
					compatible = "ethernet-phy-ieee802.3-c22";
					reg = <0x0a>;
					phy-mode = "internal";
					status = "okay";
					interrupts = <0x02>;
					pinctrl-names = "gbe-led";
					pinctrl-0 = <0x44>;
					phandle = <0x3f>;

					leds {
						#address-cells = <0x01>;
						#size-cells = <0x00>;

						led@0 {
							reg = <0x00>;
							status = "disabled";
						};

						led@1 {
							reg = <0x01>;
							status = "disabled";
						};
					};
				};

				ethernet-phy@b {
					compatible = "ethernet-phy-ieee802.3-c22";
					reg = <0x0b>;
					phy-mode = "internal";
					status = "disabled";
					phandle = <0x40>;

					leds {
						#address-cells = <0x01>;
						#size-cells = <0x00>;

						led@0 {
							reg = <0x00>;
							status = "disabled";
						};

						led@1 {
							reg = <0x01>;
							status = "disabled";
						};
					};
				};

				ethernet-phy@c {
					compatible = "ethernet-phy-ieee802.3-c22";
					reg = <0x0c>;
					phy-mode = "internal";
					status = "disabled";
					phandle = <0x41>;

					leds {
						#address-cells = <0x01>;
						#size-cells = <0x00>;

						led@0 {
							reg = <0x00>;
							status = "disabled";
						};

						led@1 {
							reg = <0x01>;
							status = "disabled";
						};
					};
				};

				ethernet-phy@5 {
					compatible = "ethernet-phy-ieee802.3-c45";
					reg = <0x05>;
					reset-gpios = <0x22 0x2e 0x01>;
					reset-assert-us = <0x30d40>;
					reset-deassert-us = <0x30d40>;
					tx-polarity = <0x01>;
					rx-polarity = <0x01>;
					phandle = <0x3c>;
				};

				ethernet-phy@8 {
					compatible = "ethernet-phy-ieee802.3-c45";
					reg = <0x08>;
					reset-gpios = <0x22 0x1f 0x01>;
					reset-assert-us = <0x30d40>;
					reset-deassert-us = <0x30d40>;
					tx-polarity = <0x01>;
					rx-polarity = <0x01>;
					phandle = <0x39>;
				};
			};
		};
	};

	aliases {
		serial0 = "/soc/serial@1fbf0000";
		led-boot = "/leds/led-2";
		led-failsafe = "/leds/led-1";
		led-upgrade = "/leds/led-1";
		led-running = "/leds/led-0";
	};

	chosen {
		rootdisk = <0x45>;
		bootargs = "console=ttyS0,115200 earlycon ubi.block=0,fit root=/dev/fit0 rootwait";
		stdout-path = "serial0:115200n8";
	};

	keys {
		compatible = "gpio-keys";

		key-restart {
			label = "reset";
			gpios = <0x22 0x00 0x01>;
			linux,code = <0x198>;
		};
	};

	leds {
		compatible = "gpio-leds";

		led-0 {
			color = <0x02>;
			function = "status";
			gpios = <0x22 0x11 0x01>;
		};

		led-1 {
			color = <0x03>;
			function = "status";
			gpios = <0x22 0x13 0x01>;
		};

		led-2 {
			color = <0x01>;
			function = "status";
			gpios = <0x22 0x1d 0x01>;
		};

		led-3 {
			color = <0x00>;
			function = "status";
			gpios = <0x22 0x14 0x01>;
		};

		led-4 {
			color = <0x02>;
			function = "lan";
			function-enumerator = <0x03>;
			gpios = <0x22 0x09 0x01>;
		};

		led-5 {
			color = <0x06>;
			function = "lan";
			function-enumerator = <0x03>;
			gpios = <0x22 0x0a 0x01>;
		};

		led-6 {
			color = <0x02>;
			function = "lan";
			function-enumerator = <0x04>;
			gpios = <0x22 0x1b 0x01>;
		};

		led-7 {
			color = <0x06>;
			function = "lan";
			function-enumerator = <0x04>;
			gpios = <0x22 0x1c 0x01>;
		};
	};
};
